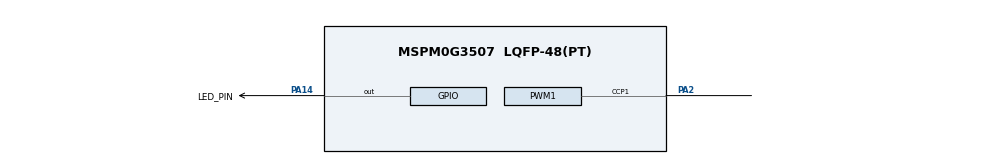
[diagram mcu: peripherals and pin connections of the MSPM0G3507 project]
/**
 * These arguments were used when this file was generated. They will be automatically applied on subsequent loads
 * via the GUI or CLI. Run CLI with '--help' for additional information on how to override these arguments.
 * @cliArgs --device "MSPM0G350X" --part "Default" --package "LQFP-48(PT)" --product "mspm0_sdk@2.10.00.04"
 * @v2CliArgs --device "MSPM0G3507" --package "LQFP-48(PT)" --product "mspm0_sdk@2.10.00.04"
 * @versions {"tool":"1.27.0+4565"}
 */

/**
 * Import the modules used in this configuration.
 */
const Board    = scripting.addModule("/ti/driverlib/Board");
const CAPTURE  = scripting.addModule("/ti/driverlib/CAPTURE", {}, false);
const CAPTURE1 = CAPTURE.addInstance();
const GPIO     = scripting.addModule("/ti/driverlib/GPIO", {}, false);
const GPIO1    = GPIO.addInstance();
const GPIO2    = GPIO.addInstance();
const PWM      = scripting.addModule("/ti/driverlib/PWM", {}, false);
const PWM1     = PWM.addInstance();
const SYSCTL   = scripting.addModule("/ti/driverlib/SYSCTL");

/**
 * Write custom configuration values to the imported modules.
 */
const divider6       = system.clockTree["PLL_CLK2X_DIV"];
divider6.divideValue = 4;

const divider7       = system.clockTree["PLL_PDIV"];
divider7.divideValue = 2;

const divider9       = system.clockTree["UDIV"];
divider9.divideValue = 2;

const gate7  = system.clockTree["MFCLKGATE"];
gate7.enable = true;

const gate8  = system.clockTree["MFPCLKGATE"];
gate8.enable = true;

const multiplier2         = system.clockTree["PLL_QDIV"];
multiplier2.multiplyValue = 10;

const mux8       = system.clockTree["HSCLKMUX"];
mux8.inputSelect = "HSCLKMUX_SYSPLL2X";


CAPTURE1.$name               = "CAPTURE_ULTRASONIC";
CAPTURE1.timerPeriod         = "50 ms";
CAPTURE1.captMode            = "PULSE_WIDTH_UP";
CAPTURE1.ccIndex             = 1;
CAPTURE1.timerStartTimer     = true;
CAPTURE1.peripheral.$assign  = "TIMG12";
CAPTURE1.ccp1PinConfig.$name = "ti_driverlib_gpio_GPIOPinGeneric0";

GPIO1.$name                         = "LED";
GPIO1.associatedPins[0].$name       = "LED_PIN";
GPIO1.associatedPins[0].pin.$assign = "PA14";

GPIO2.$name                          = "OLED";
GPIO2.associatedPins.create(2);
GPIO2.associatedPins[0].$name        = "SCL";
GPIO2.associatedPins[0].initialValue = "SET";
GPIO2.associatedPins[0].assignedPort = "PORTB";
GPIO2.associatedPins[0].assignedPin  = "2";
GPIO2.associatedPins[1].$name        = "SDA";
GPIO2.associatedPins[1].initialValue = "SET";
GPIO2.associatedPins[1].assignedPort = "PORTB";
GPIO2.associatedPins[1].assignedPin  = "3";

PWM1.$name                              = "PWM_ULTRASONIC";
PWM1.clockPrescale                      = 250;
PWM1.timerCount                         = 64000;
PWM1.timerStartTimer                    = true;
PWM1.ccIndex                            = [1];
PWM1.ccp1PinConfig.direction            = scripting.forceWrite("OUTPUT");
PWM1.ccp1PinConfig.hideOutputInversion  = scripting.forceWrite(false);
PWM1.ccp1PinConfig.onlyInternalResistor = scripting.forceWrite(false);
PWM1.ccp1PinConfig.passedPeripheralType = scripting.forceWrite("Digital");
PWM1.ccp1PinConfig.$name                = "ti_driverlib_gpio_GPIOPinGeneric1";
PWM1.peripheral.$assign                 = "TIMG8";
PWM1.peripheral.ccp1Pin.$assign         = "PA2";
PWM1.PWM_CHANNEL_1.$name                = "ti_driverlib_pwm_PWMTimerCC0";
PWM1.PWM_CHANNEL_1.dutyCycle            = 50;

SYSCTL.clockTreeEn = true;

/**
 * Pinmux solution for unlocked pins/peripherals. This ensures that minor changes to the automatic solver in a future
 * version of the tool will not impact the pinmux you originally saw.  These lines can be completely deleted in order to
 * re-solve from scratch.
 */
Board.peripheral.$suggestSolution            = "DEBUGSS";
Board.peripheral.swclkPin.$suggestSolution   = "PA20";
Board.peripheral.swdioPin.$suggestSolution   = "PA19";
CAPTURE1.peripheral.ccp1Pin.$suggestSolution = "PA25";
GPIO2.associatedPins[0].pin.$suggestSolution = "PB2";
GPIO2.associatedPins[1].pin.$suggestSolution = "PB3";
